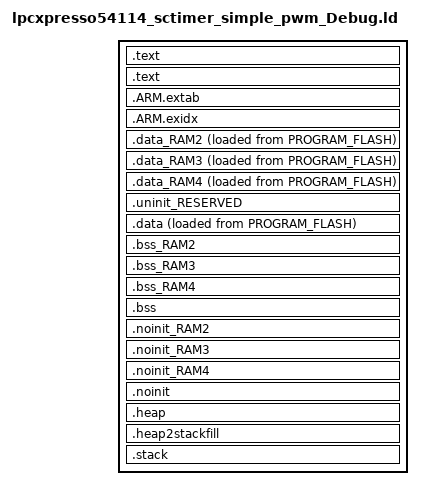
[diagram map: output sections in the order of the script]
/*
 * GENERATED FILE - DO NOT EDIT
 * Copyright (c) 2008 - 2013 Code Red Technologies Ltd, 
 * Copyright 2015, 2018 NXP
 * (c) NXP Semiconductors 2013-2019
 * Generated linker script file for LPC54114J256
 * Created from linkscript.ldt by FMCreateLinkLibraries
 * Using Freemarker v2.3.23
 * MCUXpresso IDE v10.3.1 [Build 2233] [2019-02-20] on 25-May-2019 2:23:26 PM
 */

INCLUDE "lpcxpresso54114_sctimer_simple_pwm_Debug_library.ld"
INCLUDE "lpcxpresso54114_sctimer_simple_pwm_Debug_memory.ld"

ENTRY(ResetISR)

SECTIONS
{
    /* MAIN TEXT SECTION */
    .text : ALIGN(4)
    {
        FILL(0xff)
        __vectors_start__ = ABSOLUTE(.) ;
        KEEP(*(.isr_vector))
        /* Global Section Table */
        . = ALIGN(4) ;
        __section_table_start = .;
        __data_section_table = .;
        LONG(LOADADDR(.data));
        LONG(    ADDR(.data));
        LONG(  SIZEOF(.data));
        LONG(LOADADDR(.data_RAM2));
        LONG(    ADDR(.data_RAM2));
        LONG(  SIZEOF(.data_RAM2));
        LONG(LOADADDR(.data_RAM3));
        LONG(    ADDR(.data_RAM3));
        LONG(  SIZEOF(.data_RAM3));
        LONG(LOADADDR(.data_RAM4));
        LONG(    ADDR(.data_RAM4));
        LONG(  SIZEOF(.data_RAM4));
        __data_section_table_end = .;
        __bss_section_table = .;
        LONG(    ADDR(.bss));
        LONG(  SIZEOF(.bss));
        LONG(    ADDR(.bss_RAM2));
        LONG(  SIZEOF(.bss_RAM2));
        LONG(    ADDR(.bss_RAM3));
        LONG(  SIZEOF(.bss_RAM3));
        LONG(    ADDR(.bss_RAM4));
        LONG(  SIZEOF(.bss_RAM4));
        __bss_section_table_end = .;
        __section_table_end = . ;
        /* End of Global Section Table */

        *(.after_vectors*)

    } > PROGRAM_FLASH

    .text : ALIGN(4)
    {
       *(.text*)
       *(.rodata .rodata.* .constdata .constdata.*)
       . = ALIGN(4);
    } > PROGRAM_FLASH
    /*
     * for exception handling/unwind - some Newlib functions (in common
     * with C++ and STDC++) use this. 
     */
    .ARM.extab : ALIGN(4) 
    {
        *(.ARM.extab* .gnu.linkonce.armextab.*)
    } > PROGRAM_FLASH

    __exidx_start = .;

    .ARM.exidx : ALIGN(4)
    {
        *(.ARM.exidx* .gnu.linkonce.armexidx.*)
    } > PROGRAM_FLASH
    __exidx_end = .;
 
    _etext = .;
        
    /* DATA section for SRAM0 */

    .data_RAM2 : ALIGN(4)
    {
        FILL(0xff)
        PROVIDE(__start_data_RAM2 = .) ;
        *(.ramfunc.$RAM2)
        *(.ramfunc.$SRAM0)
        *(.data.$RAM2*)
        *(.data.$SRAM0*)
        . = ALIGN(4) ;
        PROVIDE(__end_data_RAM2 = .) ;
     } > SRAM0 AT>PROGRAM_FLASH
    /* DATA section for SRAMX */

    .data_RAM3 : ALIGN(4)
    {
        FILL(0xff)
        PROVIDE(__start_data_RAM3 = .) ;
        *(.ramfunc.$RAM3)
        *(.ramfunc.$SRAMX)
        *(.data.$RAM3*)
        *(.data.$SRAMX*)
        . = ALIGN(4) ;
        PROVIDE(__end_data_RAM3 = .) ;
     } > SRAMX AT>PROGRAM_FLASH
    /* DATA section for SRAM2 */

    .data_RAM4 : ALIGN(4)
    {
        FILL(0xff)
        PROVIDE(__start_data_RAM4 = .) ;
        *(.ramfunc.$RAM4)
        *(.ramfunc.$SRAM2)
        *(.data.$RAM4*)
        *(.data.$SRAM2*)
        . = ALIGN(4) ;
        PROVIDE(__end_data_RAM4 = .) ;
     } > SRAM2 AT>PROGRAM_FLASH
    /* MAIN DATA SECTION */
    .uninit_RESERVED : ALIGN(4)
    {
        KEEP(*(.bss.$RESERVED*))
        . = ALIGN(4) ;
        _end_uninit_RESERVED = .;
    } > SRAM1

    /* Main DATA section (SRAM1) */
    .data : ALIGN(4)
    {
       FILL(0xff)
       _data = . ;
       *(vtable)
       *(.ramfunc*)
       *(.data*)
       . = ALIGN(4) ;
       _edata = . ;
    } > SRAM1 AT>PROGRAM_FLASH

    /* BSS section for SRAM0 */
    .bss_RAM2 : ALIGN(4)
    {
       PROVIDE(__start_bss_RAM2 = .) ;
       *(.bss.$RAM2*)
       *(.bss.$SRAM0*)
       . = ALIGN (. != 0 ? 4 : 1) ; /* avoid empty segment */
       PROVIDE(__end_bss_RAM2 = .) ;
    } > SRAM0 

    /* BSS section for SRAMX */
    .bss_RAM3 : ALIGN(4)
    {
       PROVIDE(__start_bss_RAM3 = .) ;
       *(.bss.$RAM3*)
       *(.bss.$SRAMX*)
       . = ALIGN (. != 0 ? 4 : 1) ; /* avoid empty segment */
       PROVIDE(__end_bss_RAM3 = .) ;
    } > SRAMX 

    /* BSS section for SRAM2 */
    .bss_RAM4 : ALIGN(4)
    {
       PROVIDE(__start_bss_RAM4 = .) ;
       *(.bss.$RAM4*)
       *(.bss.$SRAM2*)
       . = ALIGN (. != 0 ? 4 : 1) ; /* avoid empty segment */
       PROVIDE(__end_bss_RAM4 = .) ;
    } > SRAM2 

    /* MAIN BSS SECTION */
    .bss : ALIGN(4)
    {
        _bss = .;
        *(.bss*)
        *(COMMON)
        . = ALIGN(4) ;
        _ebss = .;
        PROVIDE(end = .);
    } > SRAM1

    /* NOINIT section for SRAM0 */
    .noinit_RAM2 (NOLOAD) : ALIGN(4)
    {
       *(.noinit.$RAM2*)
       *(.noinit.$SRAM0*)
       . = ALIGN(4) ;
    } > SRAM0 

    /* NOINIT section for SRAMX */
    .noinit_RAM3 (NOLOAD) : ALIGN(4)
    {
       *(.noinit.$RAM3*)
       *(.noinit.$SRAMX*)
       . = ALIGN(4) ;
    } > SRAMX 

    /* NOINIT section for SRAM2 */
    .noinit_RAM4 (NOLOAD) : ALIGN(4)
    {
       *(.noinit.$RAM4*)
       *(.noinit.$SRAM2*)
       . = ALIGN(4) ;
    } > SRAM2 

    /* DEFAULT NOINIT SECTION */
    .noinit (NOLOAD): ALIGN(4)
    {
        _noinit = .;
        *(.noinit*) 
         . = ALIGN(4) ;
        _end_noinit = .;
    } > SRAM1

    /* Reserve and place Heap within memory map */
    _HeapSize = 0x1000;
    .heap :  ALIGN(4)
    {
        _pvHeapStart = .;
        . += _HeapSize;
        . = ALIGN(4);
        _pvHeapLimit = .;
    } > SRAM1

     _StackSize = 0x1000;
     /* Reserve space in memory for Stack */
    .heap2stackfill  :
    {
        . += _StackSize;
    } > SRAM1
    /* Locate actual Stack in memory map */
    .stack ORIGIN(SRAM1) + LENGTH(SRAM1) - _StackSize - 0:  ALIGN(4)
    {
        _vStackBase = .;
        . = ALIGN(4);
        _vStackTop = . + _StackSize;
    } > SRAM1

    /* ## Create checksum value (used in startup) ## */
    PROVIDE(__valid_user_code_checksum = 0 - 
                                         (_vStackTop 
                                         + (ResetISR + 1) 
                                         + (( DEFINED(NMI_Handler) ? NMI_Handler : M0_NMI_Handler ) + 1) 
                                         + (( DEFINED(HardFault_Handler) ? HardFault_Handler : M0_HardFault_Handler ) + 1) 
                                         )
           );

    /* Provide basic symbols giving location and size of main text
     * block, including initial values of RW data sections. Note that
     * these will need extending to give a complete picture with
     * complex images (e.g multiple Flash banks).
     */
    _image_start = LOADADDR(.text);
    _image_end = LOADADDR(.data) + SIZEOF(.data);
    _image_size = _image_end - _image_start;
}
